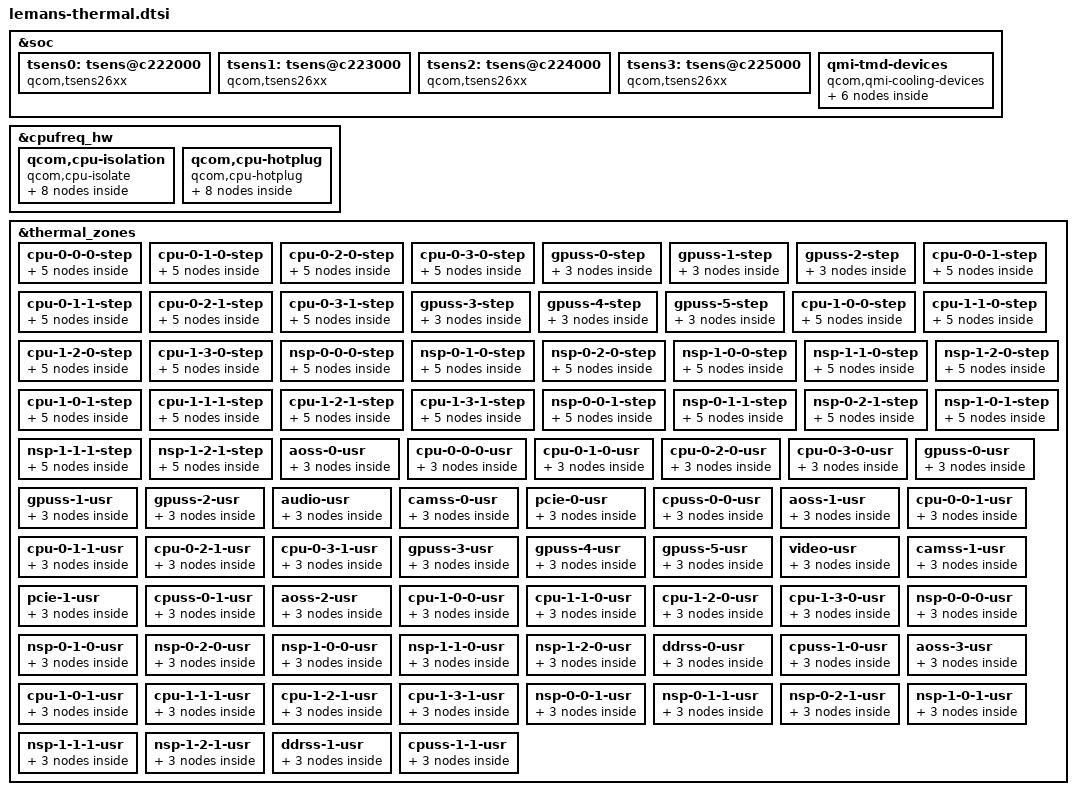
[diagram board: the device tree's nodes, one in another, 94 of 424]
#include <dt-bindings/thermal/thermal_qti.h>

&soc {
	tsens0:tsens@c222000 {
		compatible = "qcom,tsens26xx";
		reg = <0x0C222000 0x8>,
		      <0x0C263000 0x1ff>;
		reg-names = "tsens_srot_physical",
			"tsens_tm_physical";
		interrupts = <GIC_SPI 506 IRQ_TYPE_LEVEL_HIGH>,
			<GIC_SPI 508 IRQ_TYPE_LEVEL_HIGH>;
		interrupt-names = "tsens-upper-lower", "tsens-critical";
		#thermal-sensor-cells = <1>;
	};

	tsens1:tsens@c223000 {
		compatible = "qcom,tsens26xx";
		reg = <0x0C223000 0x8>,
			<0x0C265000 0x1ff>;
		reg-names = "tsens_srot_physical",
			"tsens_tm_physical";
		interrupts = <GIC_SPI 507 IRQ_TYPE_LEVEL_HIGH>,
			<GIC_SPI 509 IRQ_TYPE_LEVEL_HIGH>;
		interrupt-names = "tsens-upper-lower", "tsens-critical";
		#thermal-sensor-cells = <1>;
	};

	tsens2:tsens@c224000 {
		compatible = "qcom,tsens26xx";
		reg = <0x0C224000 0x8>,
			<0x0C251000 0x1ff>;
		reg-names = "tsens_srot_physical",
			"tsens_tm_physical";
		interrupts = <GIC_SPI 572 IRQ_TYPE_LEVEL_HIGH>,
			<GIC_SPI 609 IRQ_TYPE_LEVEL_HIGH>;
		interrupt-names = "tsens-upper-lower", "tsens-critical";
		#thermal-sensor-cells = <1>;
	};

	tsens3:tsens@c225000 {
		compatible = "qcom,tsens26xx";
		reg = <0x0C225000 0x8>,
			<0x0C252000 0x1ff>;
		reg-names = "tsens_srot_physical",
			"tsens_tm_physical";
		interrupts = <GIC_SPI 573 IRQ_TYPE_LEVEL_HIGH>,
			<GIC_SPI 610 IRQ_TYPE_LEVEL_HIGH>;
		interrupt-names = "tsens-upper-lower", "tsens-critical";
		#thermal-sensor-cells = <1>;
	};

	qmi-tmd-devices {
		compatible = "qcom,qmi-cooling-devices";

		cdsp0 {
			qcom,instance-id = <QMI_CDSP_INST_ID>;

			cdsp_sw0: cdsp_sw0 {
				qcom,qmi-dev-name = "cdsp_sw";
				#cooling-cells = <2>;
			};

			cdsp_hw0: cdsp_hw0 {
				qcom,qmi-dev-name = "cdsp_hw";
				#cooling-cells = <2>;
			};
		};

		cdsp1 {
			qcom,instance-id = <QMI_CDSP1_INST_ID>;

			cdsp_sw1: cdsp_sw1 {
				qcom,qmi-dev-name = "cdsp_sw";
				#cooling-cells = <2>;
			};

			cdsp_hw1: cdsp_hw1 {
				qcom,qmi-dev-name = "cdsp_hw";
				#cooling-cells = <2>;
			};
		};
	};
};

&cpufreq_hw {
	qcom,cpu-isolation {
		compatible = "qcom,cpu-isolate";
		cpu0_isolate: cpu0-isolate {
			qcom,cpu = <&CPU0>;
			#cooling-cells = <2>;
		};

		cpu1_isolate: cpu1-isolate {
			qcom,cpu = <&CPU1>;
			#cooling-cells = <2>;
		};

		cpu2_isolate: cpu2-isolate {
			qcom,cpu = <&CPU2>;
			#cooling-cells = <2>;
		};

		cpu3_isolate: cpu3-isolate {
			qcom,cpu = <&CPU3>;
			#cooling-cells = <2>;
		};

		cpu4_isolate: cpu4-isolate {
			qcom,cpu = <&CPU4>;
			#cooling-cells = <2>;
		};

		cpu5_isolate: cpu5-isolate {
			qcom,cpu = <&CPU5>;
			#cooling-cells = <2>;
		};

		cpu6_isolate: cpu6-isolate {
			qcom,cpu = <&CPU6>;
			#cooling-cells = <2>;
		};

		cpu7_isolate: cpu7-isolate {
			qcom,cpu = <&CPU7>;
			#cooling-cells = <2>;
		};
	};

	qcom,cpu-hotplug {
		compatible = "qcom,cpu-hotplug";
		cpu0_hotplug: cpu0-hotplug {
			qcom,cpu = <&CPU0>;
			#cooling-cells = <2>;
		};

		cpu1_hotplug: cpu1-hotplug {
			qcom,cpu = <&CPU1>;
			#cooling-cells = <2>;
		};

		cpu2_hotplug: cpu2-hotplug {
			qcom,cpu = <&CPU2>;
			#cooling-cells = <2>;
		};

		cpu3_hotplug: cpu3-hotplug {
			qcom,cpu = <&CPU3>;
			#cooling-cells = <2>;
		};

		cpu4_hotplug: cpu4-hotplug {
			qcom,cpu = <&CPU4>;
			#cooling-cells = <2>;
		};

		cpu5_hotplug: cpu5-hotplug {
			qcom,cpu = <&CPU5>;
			#cooling-cells = <2>;
		};

		cpu6_hotplug: cpu6-hotplug {
			qcom,cpu = <&CPU6>;
			#cooling-cells = <2>;
		};

		cpu7_hotplug: cpu7-hotplug {
			qcom,cpu = <&CPU7>;
			#cooling-cells = <2>;
		};
	};
};

&thermal_zones {
	cpu-0-0-0-step {
		polling-delay-passive = <0>;
		polling-delay = <0>;
		thermal-governor = "step_wise";
		thermal-sensors = <&tsens0 1>;
		trips {
			cpu000_config: cpu000-config {
				temperature = <116000>;
				hysteresis = <3000>;
				type = "passive";
			};

			cpu000_config1: cpu000-config1 {
				temperature = <115000>;
				hysteresis = <5000>;
				type = "passive";
			};
		};

		cooling-maps {
			cpu000_cdev {
				trip = <&cpu000_config>;
				cooling-device = <&cpu0_isolate 1 1>;
			};
		};
	};

	cpu-0-1-0-step {
		polling-delay-passive = <0>;
		polling-delay = <0>;
		thermal-governor = "step_wise";
		thermal-sensors = <&tsens0 2>;
		trips {
			cpu010_config: cpu010-config {
				temperature = <116000>;
				hysteresis = <3000>;
				type = "passive";
			};

			cpu010_config1: cpu010-config1 {
				temperature = <115000>;
				hysteresis = <5000>;
				type = "passive";
			};
		};

		cooling-maps {
			cpu010_cdev {
				trip = <&cpu010_config>;
				cooling-device = <&cpu1_isolate 1 1>;
			};
		};
	};

	cpu-0-2-0-step {
		polling-delay-passive = <0>;
		polling-delay = <0>;
		thermal-governor = "step_wise";
		thermal-sensors = <&tsens0 3>;
		trips {
			cpu020_config: cpu020-config {
				temperature = <116000>;
				hysteresis = <3000>;
				type = "passive";
			};

			cpu020_config1: cpu020-config1 {
				temperature = <115000>;
				hysteresis = <5000>;
				type = "passive";
			};
		};

		cooling-maps {
			cpu020_cdev {
				trip = <&cpu020_config>;
				cooling-device = <&cpu2_isolate 1 1>;
			};
		};
	};

	cpu-0-3-0-step {
		polling-delay-passive = <0>;
		polling-delay = <0>;
		thermal-governor = "step_wise";
		thermal-sensors = <&tsens0 4>;
		trips {
			cpu030_config: cpu030-config {
				temperature = <116000>;
				hysteresis = <3000>;
				type = "passive";
			};

			cpu030_config1: cpu030-config1 {
				temperature = <115000>;
				hysteresis = <5000>;
				type = "passive";
			};
		};

		cooling-maps {
			cpu030_cdev {
				trip = <&cpu030_config>;
				cooling-device = <&cpu3_isolate 1 1>;
			};
		};
	};

	gpuss-0-step {
		polling-delay-passive = <0>;
		polling-delay = <0>;
		thermal-governor = "step_wise";
		thermal-sensors = <&tsens0 5>;
		trips {
			gpuss0_config: gpuss0-config {
				temperature = <110000>;
				hysteresis = <10000>;
				type = "passive";
			};

			gpuss0_config1: gpuss0-config1 {
				temperature = <115000>;
				hysteresis = <5000>;
				type = "passive";
			};
		};
	};

	gpuss-1-step {
		polling-delay-passive = <0>;
		polling-delay = <0>;
		thermal-governor = "step_wise";
		thermal-sensors = <&tsens0 6>;
		trips {
			gpuss1_config: gpuss1-config {
				temperature = <110000>;
				hysteresis = <10000>;
				type = "passive";
			};

			gpuss1_config1: gpuss1-config1 {
				temperature = <115000>;
				hysteresis = <5000>;
				type = "passive";
			};
		};
	};

	gpuss-2-step {
		polling-delay-passive = <0>;
		polling-delay = <0>;
		thermal-governor = "step_wise";
		thermal-sensors = <&tsens0 7>;
		trips {
			gpuss2_config: gpuss2-config {
				temperature = <110000>;
				hysteresis = <10000>;
				type = "passive";
			};

			gpuss2_config1: gpuss2-config1 {
				temperature = <115000>;
				hysteresis = <5000>;
				type = "passive";
			};
		};
	};

	cpu-0-0-1-step {
		polling-delay-passive = <0>;
		polling-delay = <0>;
		thermal-governor = "step_wise";
		thermal-sensors = <&tsens1 1>;
		trips {
			cpu001_config: cpu001-config {
				temperature = <116000>;
				hysteresis = <3000>;
				type = "passive";
			};

			cpu001_config1: cpu001-config1 {
				temperature = <115000>;
				hysteresis = <5000>;
				type = "passive";
			};
		};

		cooling-maps {
			cpu001_cdev {
				trip = <&cpu001_config>;
				cooling-device = <&cpu0_isolate 1 1>;
			};
		};
	};

	cpu-0-1-1-step {
		polling-delay-passive = <0>;
		polling-delay = <0>;
		thermal-governor = "step_wise";
		thermal-sensors = <&tsens1 2>;
		trips {
			cpu011_config: cpu011-config {
				temperature = <116000>;
				hysteresis = <3000>;
				type = "passive";
			};

			cpu011_config1: cpu011-config1 {
				temperature = <115000>;
				hysteresis = <5000>;
				type = "passive";
			};
		};

		cooling-maps {
			cpu011_cdev {
				trip = <&cpu011_config>;
				cooling-device = <&cpu1_isolate 1 1>;
			};
		};
	};

	cpu-0-2-1-step {
		polling-delay-passive = <0>;
		polling-delay = <0>;
		thermal-governor = "step_wise";
		thermal-sensors = <&tsens1 3>;
		trips {
			cpu021_config: cpu021-config {
				temperature = <116000>;
				hysteresis = <3000>;
				type = "passive";
			};

			cpu021_config1: cpu021-config1 {
				temperature = <115000>;
				hysteresis = <5000>;
				type = "passive";
			};
		};

		cooling-maps {
			cpu021_cdev {
				trip = <&cpu021_config>;
				cooling-device = <&cpu2_isolate 1 1>;
			};
		};
	};

	cpu-0-3-1-step {
		polling-delay-passive = <0>;
		polling-delay = <0>;
		thermal-governor = "step_wise";
		thermal-sensors = <&tsens1 4>;
		trips {
			cpu031_config: cpu031-config {
				temperature = <116000>;
				hysteresis = <3000>;
				type = "passive";
			};

			cpu031_config1: cpu031-config1 {
				temperature = <115000>;
				hysteresis = <5000>;
				type = "passive";
			};
		};

		cooling-maps {
			cpu031_cdev {
				trip = <&cpu031_config>;
				cooling-device = <&cpu3_isolate 1 1>;
			};
		};
	};

	gpuss-3-step {
		polling-delay-passive = <0>;
		polling-delay = <0>;
		thermal-governor = "step_wise";
		thermal-sensors = <&tsens1 5>;
		trips {
			gpuss3_config: gpuss3-config {
				temperature = <110000>;
				hysteresis = <10000>;
				type = "passive";
			};

			gpuss3_config1: gpuss3-config1 {
				temperature = <115000>;
				hysteresis = <5000>;
				type = "passive";
			};
		};
	};

	gpuss-4-step {
		polling-delay-passive = <0>;
		polling-delay = <0>;
		thermal-governor = "step_wise";
		thermal-sensors = <&tsens1 6>;
		trips {
			gpuss4_config: gpuss4-config {
				temperature = <110000>;
				hysteresis = <10000>;
				type = "passive";
			};

			gpuss4_config1: gpuss4-config1 {
				temperature = <115000>;
				hysteresis = <5000>;
				type = "passive";
			};
		};
	};

	gpuss-5-step {
		polling-delay-passive = <0>;
		polling-delay = <0>;
		thermal-governor = "step_wise";
		thermal-sensors = <&tsens1 7>;
		trips {
			gpuss5_config: gpuss5-config {
				temperature = <110000>;
				hysteresis = <10000>;
				type = "passive";
			};

			gpuss5_config1: gpuss5-config1 {
				temperature = <115000>;
				hysteresis = <5000>;
				type = "passive";
			};
		};
	};

	cpu-1-0-0-step {
		polling-delay-passive = <0>;
		polling-delay = <0>;
		thermal-governor = "step_wise";
		thermal-sensors = <&tsens2 1>;
		trips {
			cpu100_config: cpu100-config {
				temperature = <116000>;
				hysteresis = <3000>;
				type = "passive";
			};

			cpu100_config1: cpu100-config1 {
				temperature = <115000>;
				hysteresis = <5000>;
				type = "passive";
			};
		};

		cooling-maps {
			cpu100_cdev {
				trip = <&cpu100_config>;
				cooling-device = <&cpu4_isolate 1 1>;
			};
		};
	};

	cpu-1-1-0-step {
		polling-delay-passive = <0>;
		polling-delay = <0>;
		thermal-governor = "step_wise";
		thermal-sensors = <&tsens2 2>;
		trips {
			cpu110_config: cpu110-config {
				temperature = <116000>;
				hysteresis = <3000>;
				type = "passive";
			};

			cpu110_config1: cpu110-config1 {
				temperature = <115000>;
				hysteresis = <5000>;
				type = "passive";
			};
		};

		cooling-maps {
			cpu110_cdev {
				trip = <&cpu110_config>;
				cooling-device = <&cpu5_isolate 1 1>;
			};
		};
	};

	cpu-1-2-0-step {
		polling-delay-passive = <0>;
		polling-delay = <0>;
		thermal-governor = "step_wise";
		thermal-sensors = <&tsens2 3>;
		trips {
			cpu120_config: cpu120-config {
				temperature = <116000>;
				hysteresis = <3000>;
				type = "passive";
			};

			cpu120_config1: cpu120-config1 {
				temperature = <115000>;
				hysteresis = <5000>;
				type = "passive";
			};
		};

		cooling-maps {
			cpu120_cdev {
				trip = <&cpu120_config>;
				cooling-device = <&cpu6_isolate 1 1>;
			};
		};
	};

	cpu-1-3-0-step {
		polling-delay-passive = <0>;
		polling-delay = <0>;
		thermal-governor = "step_wise";
		thermal-sensors = <&tsens2 4>;
		trips {
			cpu130_config: cpu130-config {
				temperature = <116000>;
				hysteresis = <3000>;
				type = "passive";
			};

			cpu130_config1: cpu130-config1 {
				temperature = <115000>;
				hysteresis = <5000>;
				type = "passive";
			};
		};

		cooling-maps {
			cpu130_cdev {
				trip = <&cpu130_config>;
				cooling-device = <&cpu7_isolate 1 1>;
			};
		};
	};

	nsp-0-0-0-step {
		polling-delay-passive = <0>;
		polling-delay = <0>;
		thermal-governor = "step_wise";
		thermal-sensors = <&tsens2 5>;
		trips {
			nsp000_config: nsp000-config {
				temperature = <105000>;
				hysteresis = <10000>;
				type = "passive";
			};

			nsp000_config1: nsp000-config1 {
				temperature = <115000>;
				hysteresis = <5000>;
				type = "passive";
			};
		};

		cooling-maps {
			nsp000_cdev {
				trip = <&nsp000_config>;
				cooling-device = <&cdsp_sw0 THERMAL_NO_LIMIT
								THERMAL_NO_LIMIT>;
			};
		};
	};

	nsp-0-1-0-step {
		polling-delay-passive = <0>;
		polling-delay = <0>;
		thermal-governor = "step_wise";
		thermal-sensors = <&tsens2 6>;
		trips {
			nsp010_config: nsp010-config {
				temperature = <105000>;
				hysteresis = <10000>;
				type = "passive";
			};

			nsp010_config1: nsp010-config1 {
				temperature = <115000>;
				hysteresis = <5000>;
				type = "passive";
			};
		};

		cooling-maps {
			nsp010_cdev {
				trip = <&nsp010_config>;
				cooling-device = <&cdsp_sw0 THERMAL_NO_LIMIT
								THERMAL_NO_LIMIT>;
			};
		};
	};

	nsp-0-2-0-step {
		polling-delay-passive = <0>;
		polling-delay = <0>;
		thermal-governor = "step_wise";
		thermal-sensors = <&tsens2 7>;
		trips {
			nsp020_config: nsp020-config {
				temperature = <105000>;
				hysteresis = <10000>;
				type = "passive";
			};

			nsp020_config1: nsp020-config1 {
				temperature = <115000>;
				hysteresis = <5000>;
				type = "passive";
			};
		};

		cooling-maps {
			nsp020_cdev {
				trip = <&nsp020_config>;
				cooling-device = <&cdsp_sw0 THERMAL_NO_LIMIT
								THERMAL_NO_LIMIT>;
			};
		};
	};

	nsp-1-0-0-step {
		polling-delay-passive = <0>;
		polling-delay = <0>;
		thermal-governor = "step_wise";
		thermal-sensors = <&tsens2 8>;
		trips {
			nsp100_config: nsp100-config {
				temperature = <105000>;
				hysteresis = <10000>;
				type = "passive";
			};

			nsp100_config1: nsp100-config1 {
				temperature = <115000>;
				hysteresis = <5000>;
				type = "passive";
			};
		};

		cooling-maps {
			nsp100_cdev {
				trip = <&nsp100_config>;
				cooling-device = <&cdsp_sw1 THERMAL_NO_LIMIT
								THERMAL_NO_LIMIT>;
			};
		};
	};

	nsp-1-1-0-step {
		polling-delay-passive = <0>;
		polling-delay = <0>;
		thermal-governor = "step_wise";
		thermal-sensors = <&tsens2 9>;
		trips {
			nsp110_config: nsp110-config {
				temperature = <105000>;
				hysteresis = <10000>;
				type = "passive";
			};

			nsp110_config1: nsp110-config1 {
				temperature = <115000>;
				hysteresis = <5000>;
				type = "passive";
			};
		};

		cooling-maps {
			nsp110_cdev {
				trip = <&nsp110_config>;
				cooling-device = <&cdsp_sw1 THERMAL_NO_LIMIT
								THERMAL_NO_LIMIT>;
			};
		};
	};

	nsp-1-2-0-step {
		polling-delay-passive = <0>;
		polling-delay = <0>;
		thermal-governor = "step_wise";
		thermal-sensors = <&tsens2 10>;
		trips {
			nsp120_config: nsp120-config {
				temperature = <105000>;
				hysteresis = <10000>;
				type = "passive";
			};

			nsp120_config1: nsp120-config1 {
				temperature = <115000>;
				hysteresis = <5000>;
				type = "passive";
			};
		};

		cooling-maps {
			nsp120_cdev {
				trip = <&nsp120_config>;
				cooling-device = <&cdsp_sw1 THERMAL_NO_LIMIT
								THERMAL_NO_LIMIT>;
			};
		};
	};

	cpu-1-0-1-step {
		polling-delay-passive = <0>;
		polling-delay = <0>;
		thermal-governor = "step_wise";
		thermal-sensors = <&tsens3 1>;
		trips {
			cpu101_config: cpu101-config {
				temperature = <116000>;
				hysteresis = <3000>;
				type = "passive";
			};

			cpu101_config1: cpu101-config1 {
				temperature = <115000>;
				hysteresis = <5000>;
				type = "passive";
			};
		};

		cooling-maps {
			cpu101_cdev {
				trip = <&cpu101_config>;
				cooling-device = <&cpu4_isolate 1 1>;
			};
		};
	};

	cpu-1-1-1-step {
		polling-delay-passive = <0>;
		polling-delay = <0>;
		thermal-governor = "step_wise";
		thermal-sensors = <&tsens3 2>;
		trips {
			cpu111_config: cpu111-config {
				temperature = <116000>;
				hysteresis = <3000>;
				type = "passive";
			};

			cpu111_config1: cpu111-config1 {
				temperature = <115000>;
				hysteresis = <5000>;
				type = "passive";
			};
		};

		cooling-maps {
			cpu111_cdev {
				trip = <&cpu111_config>;
				cooling-device = <&cpu5_isolate 1 1>;
			};
		};
	};

	cpu-1-2-1-step {
		polling-delay-passive = <0>;
		polling-delay = <0>;
		thermal-governor = "step_wise";
		thermal-sensors = <&tsens3 3>;
		trips {
			cpu121_config: cpu121-config {
				temperature = <116000>;
				hysteresis = <3000>;
				type = "passive";
			};

			cpu121_config1: cpu121-config1 {
				temperature = <115000>;
				hysteresis = <5000>;
				type = "passive";
			};
		};

		cooling-maps {
			cpu121_cdev {
				trip = <&cpu121_config>;
				cooling-device = <&cpu6_isolate 1 1>;
			};
		};
	};

	cpu-1-3-1-step {
		polling-delay-passive = <0>;
		polling-delay = <0>;
		thermal-governor = "step_wise";
		thermal-sensors = <&tsens3 4>;
		trips {
			cpu131_config: cpu131-config {
				temperature = <116000>;
				hysteresis = <3000>;
				type = "passive";
			};

			cpu131_config1: cpu131-config1 {
				temperature = <115000>;
				hysteresis = <5000>;
				type = "passive";
			};
		};

		cooling-maps {
			cpu131_cdev {
				trip = <&cpu131_config>;
				cooling-device = <&cpu7_isolate 1 1>;
			};
		};
	};

	nsp-0-0-1-step {
		polling-delay-passive = <0>;
		polling-delay = <0>;
		thermal-governor = "step_wise";
		thermal-sensors = <&tsens3 5>;
		trips {
			nsp001_config: nsp001-config {
				temperature = <105000>;
				hysteresis = <10000>;
				type = "passive";
			};

			nsp001_config1: nsp001-config1 {
				temperature = <115000>;
				hysteresis = <5000>;
				type = "passive";
			};
		};

		cooling-maps {
			nsp001_cdev {
				trip = <&nsp001_config>;
				cooling-device = <&cdsp_sw0 THERMAL_NO_LIMIT
								THERMAL_NO_LIMIT>;
			};
		};
	};

	nsp-0-1-1-step {
		polling-delay-passive = <0>;
		polling-delay = <0>;
		thermal-governor = "step_wise";
		thermal-sensors = <&tsens3 6>;
		trips {
			nsp011_config: nsp011-config {
				temperature = <105000>;
				hysteresis = <10000>;
				type = "passive";
			};

			nsp011_config1: nsp011-config1 {
				temperature = <115000>;
				hysteresis = <5000>;
				type = "passive";
			};
		};

		cooling-maps {
			nsp011_cdev {
				trip = <&nsp011_config>;
				cooling-device = <&cdsp_sw0 THERMAL_NO_LIMIT
								THERMAL_NO_LIMIT>;
			};
		};
	};

	nsp-0-2-1-step {
		polling-delay-passive = <0>;
		polling-delay = <0>;
		thermal-governor = "step_wise";
		thermal-sensors = <&tsens3 7>;
		trips {
			nsp021_config: nsp021-config {
				temperature = <105000>;
				hysteresis = <10000>;
				type = "passive";
			};

			nsp021_config1: nsp021-config1 {
				temperature = <115000>;
				hysteresis = <5000>;
				type = "passive";
			};
		};

		cooling-maps {
			nsp021_cdev {
				trip = <&nsp021_config>;
				cooling-device = <&cdsp_sw0 THERMAL_NO_LIMIT
								THERMAL_NO_LIMIT>;
			};
		};
	};

	nsp-1-0-1-step {
		polling-delay-passive = <0>;
		polling-delay = <0>;
		thermal-governor = "step_wise";
		thermal-sensors = <&tsens3 8>;
		trips {
			nsp101_config: nsp101-config {
				temperature = <105000>;
				hysteresis = <10000>;
				type = "passive";
			};

			nsp101_config1: nsp101-config1 {
				temperature = <115000>;
				hysteresis = <5000>;
				type = "passive";
			};
		};

		cooling-maps {
			nsp101_cdev {
				trip = <&nsp101_config>;
				cooling-device = <&cdsp_sw1 THERMAL_NO_LIMIT
								THERMAL_NO_LIMIT>;
			};
		};
	};

	nsp-1-1-1-step {
		polling-delay-passive = <0>;
		polling-delay = <0>;
		thermal-governor = "step_wise";
		thermal-sensors = <&tsens3 9>;
		trips {
			nsp111_config: nsp111-config {
				temperature = <105000>;
				hysteresis = <10000>;
				type = "passive";
			};

			nsp111_config1: nsp111-config1 {
				temperature = <115000>;
				hysteresis = <5000>;
				type = "passive";
			};
		};

		cooling-maps {
			nsp111_cdev {
				trip = <&nsp111_config>;
				cooling-device = <&cdsp_sw1 THERMAL_NO_LIMIT
								THERMAL_NO_LIMIT>;
			};
		};
	};

	nsp-1-2-1-step {
		polling-delay-passive = <0>;
		polling-delay = <0>;
		thermal-governor = "step_wise";
		thermal-sensors = <&tsens3 10>;
		trips {
			nsp121_config: nsp121-config {
				temperature = <105000>;
				hysteresis = <10000>;
				type = "passive";
			};

			nsp121_config1: nsp121-config1 {
				temperature = <115000>;
				hysteresis = <5000>;
				type = "passive";
			};
		};

		cooling-maps {
			nsp121_cdev {
				trip = <&nsp121_config>;
				cooling-device = <&cdsp_sw1 THERMAL_NO_LIMIT
								THERMAL_NO_LIMIT>;
			};
		};
	};

	aoss-0-usr {
		polling-delay-passive = <0>;
		polling-delay = <0>;
		thermal-governor = "user_space";
		thermal-sensors = <&tsens0 0>;
		trips {
			active-config0 {
				temperature = <125000>;
				hysteresis = <1000>;
				type = "passive";
			};

			reset-mon-cfg {
				temperature = <115000>;
				hysteresis = <5000>;
				type = "passive";
			};
		};
	};

	cpu-0-0-0-usr {
		polling-delay-passive = <0>;
		polling-delay = <0>;
		thermal-governor = "user_space";
		thermal-sensors = <&tsens0 1>;
		trips {
			active-config0 {
				temperature = <125000>;
				hysteresis = <1000>;
				type = "passive";
			};

			reset-mon-cfg {
				temperature = <115000>;
				hysteresis = <5000>;
				type = "passive";
			};
		};
	};

	cpu-0-1-0-usr {
		polling-delay-passive = <0>;
		polling-delay = <0>;
		thermal-governor = "user_space";
		thermal-sensors = <&tsens0 2>;
		trips {
			active-config0 {
				temperature = <125000>;
				hysteresis = <1000>;
				type = "passive";
			};

			reset-mon-cfg {
				temperature = <115000>;
				hysteresis = <5000>;
				type = "passive";
			};
		};
	};

	cpu-0-2-0-usr {
		polling-delay-passive = <0>;
		polling-delay = <0>;
		thermal-governor = "user_space";
		thermal-sensors = <&tsens0 3>;
		trips {
			active-config0 {
				temperature = <125000>;
				hysteresis = <1000>;
				type = "passive";
			};

			reset-mon-cfg {
				temperature = <115000>;
				hysteresis = <5000>;
				type = "passive";
			};
		};
	};

	cpu-0-3-0-usr {
		polling-delay-passive = <0>;
		polling-delay = <0>;
		thermal-governor = "user_space";
		thermal-sensors = <&tsens0 4>;
		trips {
			active-config0 {
				temperature = <125000>;
				hysteresis = <1000>;
				type = "passive";
			};

			reset-mon-cfg {
				temperature = <115000>;
				hysteresis = <5000>;
				type = "passive";
			};
		};
	};

	gpuss-0-usr {
		polling-delay-passive = <0>;
		polling-delay = <0>;
		thermal-governor = "user_space";
		thermal-sensors = <&tsens0 5>;
		trips {
			active-config0 {
				temperature = <125000>;
				hysteresis = <1000>;
				type = "passive";
			};

			reset-mon-cfg {
				temperature = <115000>;
				hysteresis = <5000>;
				type = "passive";
			};
		};
	};

	gpuss-1-usr {
		polling-delay-passive = <0>;
		polling-delay = <0>;
		thermal-governor = "user_space";
		thermal-sensors = <&tsens0 6>;
		trips {
			active-config0 {
				temperature = <125000>;
				hysteresis = <1000>;
				type = "passive";
			};

			reset-mon-cfg {
				temperature = <115000>;
				hysteresis = <5000>;
				type = "passive";
			};
		};
	};

	gpuss-2-usr {
		polling-delay-passive = <0>;
		polling-delay = <0>;
		thermal-governor = "user_space";
		thermal-sensors = <&tsens0 7>;
		trips {
			active-config0 {
				temperature = <125000>;
				hysteresis = <1000>;
				type = "passive";
			};

			reset-mon-cfg {
				temperature = <115000>;
				hysteresis = <5000>;
				type = "passive";
			};
		};
	};

	audio-usr {
		polling-delay-passive = <0>;
		polling-delay = <0>;
		thermal-governor = "user_space";
		thermal-sensors = <&tsens0 8>;
		trips {
			active-config0 {
				temperature = <125000>;
				hysteresis = <1000>;
				type = "passive";
			};

			reset-mon-cfg {
				temperature = <115000>;
				hysteresis = <5000>;
				type = "passive";
			};
		};
	};

	camss-0-usr {
		polling-delay-passive = <0>;
		polling-delay = <0>;
		thermal-governor = "user_space";
		thermal-sensors = <&tsens0 9>;
		trips {
			active-config0 {
				temperature = <125000>;
				hysteresis = <1000>;
				type = "passive";
			};

			reset-mon-cfg {
				temperature = <115000>;
				hysteresis = <5000>;
				type = "passive";
			};
		};
	};

	pcie-0-usr {
		polling-delay-passive = <0>;
		polling-delay = <0>;
		thermal-governor = "user_space";
		thermal-sensors = <&tsens0 10>;
		trips {
			active-config0 {
				temperature = <125000>;
				hysteresis = <1000>;
				type = "passive";
			};

			reset-mon-cfg {
				temperature = <115000>;
				hysteresis = <5000>;
				type = "passive";
			};
		};
	};

	cpuss-0-0-usr {
		polling-delay-passive = <0>;
		polling-delay = <0>;
		thermal-governor = "user_space";
		thermal-sensors = <&tsens0 11>;
		trips {
			active-config0 {
				temperature = <125000>;
				hysteresis = <1000>;
				type = "passive";
			};

			reset-mon-cfg {
				temperature = <115000>;
				hysteresis = <5000>;
				type = "passive";
			};
		};
	};

	aoss-1-usr {
		polling-delay-passive = <0>;
		polling-delay = <0>;
		thermal-governor = "user_space";
		thermal-sensors = <&tsens1 0>;
		trips {
			active-config0 {
				temperature = <125000>;
				hysteresis = <1000>;
				type = "passive";
			};

			reset-mon-cfg {
				temperature = <115000>;
				hysteresis = <5000>;
				type = "passive";
			};
		};
	};

	cpu-0-0-1-usr {
		polling-delay-passive = <0>;
		polling-delay = <0>;
		thermal-governor = "user_space";
		thermal-sensors = <&tsens1 1>;
		trips {
			active-config0 {
				temperature = <125000>;
				hysteresis = <1000>;
				type = "passive";
			};

			reset-mon-cfg {
				temperature = <115000>;
				hysteresis = <5000>;
				type = "passive";
			};
		};
	};

	cpu-0-1-1-usr {
		polling-delay-passive = <0>;
		polling-delay = <0>;
		thermal-governor = "user_space";
		thermal-sensors = <&tsens1 2>;
		trips {
			active-config0 {
				temperature = <125000>;
				hysteresis = <1000>;
				type = "passive";
			};

			reset-mon-cfg {
				temperature = <115000>;
				hysteresis = <5000>;
				type = "passive";
			};
		};
	};

	cpu-0-2-1-usr {
		polling-delay-passive = <0>;
		polling-delay = <0>;
		thermal-governor = "user_space";
		thermal-sensors = <&tsens1 3>;
		trips {
			active-config0 {
				temperature = <125000>;
				hysteresis = <1000>;
				type = "passive";
			};

			reset-mon-cfg {
				temperature = <115000>;
				hysteresis = <5000>;
				type = "passive";
			};
		};
	};

	cpu-0-3-1-usr {
		polling-delay-passive = <0>;
		polling-delay = <0>;
		thermal-governor = "user_space";
		thermal-sensors = <&tsens1 4>;
		trips {
			active-config0 {
				temperature = <125000>;
				hysteresis = <1000>;
				type = "passive";
			};

			reset-mon-cfg {
				temperature = <115000>;
				hysteresis = <5000>;
				type = "passive";
			};
		};
	};

	gpuss-3-usr {
		polling-delay-passive = <0>;
		polling-delay = <0>;
		thermal-governor = "user_space";
		thermal-sensors = <&tsens1 5>;
		trips {
			active-config0 {
				temperature = <125000>;
				hysteresis = <1000>;
				type = "passive";
			};

			reset-mon-cfg {
				temperature = <115000>;
				hysteresis = <5000>;
				type = "passive";
			};
		};
	};

	gpuss-4-usr {
		polling-delay-passive = <0>;
		polling-delay = <0>;
		thermal-governor = "user_space";
		thermal-sensors = <&tsens1 6>;
		trips {
			active-config0 {
				temperature = <125000>;
				hysteresis = <1000>;
				type = "passive";
			};

			reset-mon-cfg {
				temperature = <115000>;
				hysteresis = <5000>;
				type = "passive";
			};
		};
	};

	gpuss-5-usr {
		polling-delay-passive = <0>;
		polling-delay = <0>;
		thermal-governor = "user_space";
		thermal-sensors = <&tsens1 7>;
		trips {
			active-config0 {
				temperature = <125000>;
				hysteresis = <1000>;
				type = "passive";
			};

			reset-mon-cfg {
				temperature = <115000>;
				hysteresis = <5000>;
				type = "passive";
			};
		};
	};

	video-usr {
		polling-delay-passive = <0>;
		polling-delay = <0>;
		thermal-governor = "user_space";
		thermal-sensors = <&tsens1 8>;
		trips {
			active-config0 {
				temperature = <125000>;
				hysteresis = <1000>;
				type = "passive";
			};

			reset-mon-cfg {
				temperature = <115000>;
				hysteresis = <5000>;
				type = "passive";
			};
		};
	};

	camss-1-usr {
		polling-delay-passive = <0>;
		polling-delay = <0>;
		thermal-governor = "user_space";
		thermal-sensors = <&tsens1 9>;
		trips {
			active-config0 {
				temperature = <125000>;
				hysteresis = <1000>;
				type = "passive";
			};

			reset-mon-cfg {
				temperature = <115000>;
				hysteresis = <5000>;
				type = "passive";
			};
		};
	};

	pcie-1-usr {
		polling-delay-passive = <0>;
		polling-delay = <0>;
		thermal-governor = "user_space";
		thermal-sensors = <&tsens1 10>;
		trips {
			active-config0 {
				temperature = <125000>;
				hysteresis = <1000>;
				type = "passive";
			};

			reset-mon-cfg {
				temperature = <115000>;
				hysteresis = <5000>;
				type = "passive";
			};
		};
	};

	cpuss-0-1-usr {
		polling-delay-passive = <0>;
		polling-delay = <0>;
		thermal-governor = "user_space";
		thermal-sensors = <&tsens1 11>;
		trips {
			active-config0 {
				temperature = <125000>;
				hysteresis = <1000>;
				type = "passive";
			};

			reset-mon-cfg {
				temperature = <115000>;
				hysteresis = <5000>;
				type = "passive";
			};
		};
	};

	aoss-2-usr {
		polling-delay-passive = <0>;
		polling-delay = <0>;
		thermal-governor = "user_space";
		thermal-sensors = <&tsens2 0>;
		trips {
			active-config0 {
				temperature = <125000>;
				hysteresis = <1000>;
				type = "passive";
			};

			reset-mon-cfg {
				temperature = <115000>;
				hysteresis = <5000>;
				type = "passive";
			};
		};
	};

	cpu-1-0-0-usr {
		polling-delay-passive = <0>;
		polling-delay = <0>;
		thermal-governor = "user_space";
		thermal-sensors = <&tsens2 1>;
		trips {
			active-config0 {
				temperature = <125000>;
				hysteresis = <1000>;
				type = "passive";
			};

			reset-mon-cfg {
				temperature = <115000>;
				hysteresis = <5000>;
				type = "passive";
			};
		};
	};

	cpu-1-1-0-usr {
		polling-delay-passive = <0>;
		polling-delay = <0>;
		thermal-governor = "user_space";
		thermal-sensors = <&tsens2 2>;
		trips {
			active-config0 {
				temperature = <125000>;
				hysteresis = <1000>;
				type = "passive";
			};

			reset-mon-cfg {
				temperature = <115000>;
				hysteresis = <5000>;
				type = "passive";
			};
		};
	};

	cpu-1-2-0-usr {
		polling-delay-passive = <0>;
		polling-delay = <0>;
		thermal-governor = "user_space";
		thermal-sensors = <&tsens2 3>;
		trips {
			active-config0 {
				temperature = <125000>;
				hysteresis = <1000>;
				type = "passive";
			};

			reset-mon-cfg {
				temperature = <115000>;
				hysteresis = <5000>;
				type = "passive";
			};
		};
	};

	cpu-1-3-0-usr {
		polling-delay-passive = <0>;
		polling-delay = <0>;
		thermal-governor = "user_space";
		thermal-sensors = <&tsens2 4>;
		trips {
			active-config0 {
				temperature = <125000>;
				hysteresis = <1000>;
				type = "passive";
			};

			reset-mon-cfg {
				temperature = <115000>;
				hysteresis = <5000>;
				type = "passive";
			};
		};
	};

	nsp-0-0-0-usr {
		polling-delay-passive = <0>;
		polling-delay = <0>;
		thermal-governor = "user_space";
		thermal-sensors = <&tsens2 5>;
		trips {
			active-config0 {
				temperature = <125000>;
				hysteresis = <1000>;
				type = "passive";
			};

			reset-mon-cfg {
				temperature = <115000>;
				hysteresis = <5000>;
				type = "passive";
			};
		};
	};

	nsp-0-1-0-usr {
		polling-delay-passive = <0>;
		polling-delay = <0>;
		thermal-governor = "user_space";
		thermal-sensors = <&tsens2 6>;
		trips {
			active-config0 {
				temperature = <125000>;
				hysteresis = <1000>;
				type = "passive";
			};

			reset-mon-cfg {
				temperature = <115000>;
				hysteresis = <5000>;
				type = "passive";
			};
		};
	};

	nsp-0-2-0-usr {
		polling-delay-passive = <0>;
		polling-delay = <0>;
		thermal-governor = "user_space";
		thermal-sensors = <&tsens2 7>;
		trips {
			active-config0 {
				temperature = <125000>;
				hysteresis = <1000>;
				type = "passive";
			};

			reset-mon-cfg {
				temperature = <115000>;
				hysteresis = <5000>;
				type = "passive";
			};
		};
	};

	nsp-1-0-0-usr {
		polling-delay-passive = <0>;
		polling-delay = <0>;
		thermal-governor = "user_space";
		thermal-sensors = <&tsens2 8>;
		trips {
			active-config0 {
				temperature = <125000>;
				hysteresis = <1000>;
				type = "passive";
			};

			reset-mon-cfg {
				temperature = <115000>;
				hysteresis = <5000>;
				type = "passive";
			};
		};
	};

	nsp-1-1-0-usr {
		polling-delay-passive = <0>;
		polling-delay = <0>;
		thermal-governor = "user_space";
		thermal-sensors = <&tsens2 9>;
		trips {
			active-config0 {
				temperature = <125000>;
				hysteresis = <1000>;
				type = "passive";
			};

			reset-mon-cfg {
				temperature = <115000>;
				hysteresis = <5000>;
				type = "passive";
			};
		};
	};

	nsp-1-2-0-usr {
		polling-delay-passive = <0>;
		polling-delay = <0>;
		thermal-governor = "user_space";
		thermal-sensors = <&tsens2 10>;
		trips {
			active-config0 {
				temperature = <125000>;
				hysteresis = <1000>;
				type = "passive";
			};

			reset-mon-cfg {
				temperature = <115000>;
				hysteresis = <5000>;
				type = "passive";
			};
		};
	};

	ddrss-0-usr {
		polling-delay-passive = <0>;
		polling-delay = <0>;
		thermal-governor = "user_space";
		thermal-sensors = <&tsens2 11>;
		trips {
			active-config0 {
				temperature = <125000>;
				hysteresis = <1000>;
				type = "passive";
			};

			reset-mon-cfg {
				temperature = <115000>;
				hysteresis = <5000>;
				type = "passive";
			};
		};
	};

	cpuss-1-0-usr {
		polling-delay-passive = <0>;
		polling-delay = <0>;
		thermal-governor = "user_space";
		thermal-sensors = <&tsens2 12>;
		trips {
			active-config0 {
				temperature = <125000>;
				hysteresis = <1000>;
				type = "passive";
			};

			reset-mon-cfg {
				temperature = <115000>;
				hysteresis = <5000>;
				type = "passive";
			};
		};
	};

	aoss-3-usr {
		polling-delay-passive = <0>;
		polling-delay = <0>;
		thermal-governor = "user_space";
		thermal-sensors = <&tsens3 0>;
		trips {
			active-config0 {
				temperature = <125000>;
				hysteresis = <1000>;
				type = "passive";
			};

			reset-mon-cfg {
				temperature = <115000>;
				hysteresis = <5000>;
				type = "passive";
			};
		};
	};

	cpu-1-0-1-usr {
		polling-delay-passive = <0>;
		polling-delay = <0>;
		thermal-governor = "user_space";
		thermal-sensors = <&tsens3 1>;
		trips {
			active-config0 {
				temperature = <125000>;
				hysteresis = <1000>;
				type = "passive";
			};

			reset-mon-cfg {
				temperature = <115000>;
				hysteresis = <5000>;
				type = "passive";
			};
		};
	};

	cpu-1-1-1-usr {
		polling-delay-passive = <0>;
		polling-delay = <0>;
		thermal-governor = "user_space";
		thermal-sensors = <&tsens3 2>;
		trips {
			active-config0 {
				temperature = <125000>;
				hysteresis = <1000>;
				type = "passive";
			};

			reset-mon-cfg {
				temperature = <115000>;
				hysteresis = <5000>;
				type = "passive";
			};
		};
	};

	cpu-1-2-1-usr {
		polling-delay-passive = <0>;
		polling-delay = <0>;
		thermal-governor = "user_space";
		thermal-sensors = <&tsens3 3>;
		trips {
			active-config0 {
				temperature = <125000>;
				hysteresis = <1000>;
				type = "passive";
			};

			reset-mon-cfg {
				temperature = <115000>;
				hysteresis = <5000>;
				type = "passive";
			};
		};
	};

	cpu-1-3-1-usr {
		polling-delay-passive = <0>;
		polling-delay = <0>;
		thermal-governor = "user_space";
		thermal-sensors = <&tsens3 4>;
		trips {
			active-config0 {
				temperature = <125000>;
				hysteresis = <1000>;
				type = "passive";
			};

			reset-mon-cfg {
				temperature = <115000>;
				hysteresis = <5000>;
				type = "passive";
			};
		};
	};

	nsp-0-0-1-usr {
		polling-delay-passive = <0>;
		polling-delay = <0>;
		thermal-governor = "user_space";
		thermal-sensors = <&tsens3 5>;
		trips {
			active-config0 {
				temperature = <125000>;
				hysteresis = <1000>;
				type = "passive";
			};

			reset-mon-cfg {
				temperature = <115000>;
				hysteresis = <5000>;
				type = "passive";
			};
		};
	};

	nsp-0-1-1-usr {
		polling-delay-passive = <0>;
		polling-delay = <0>;
		thermal-governor = "user_space";
		thermal-sensors = <&tsens3 6>;
		trips {
			active-config0 {
				temperature = <125000>;
				hysteresis = <1000>;
				type = "passive";
			};

			reset-mon-cfg {
				temperature = <115000>;
				hysteresis = <5000>;
				type = "passive";
			};
		};
	};

	nsp-0-2-1-usr {
		polling-delay-passive = <0>;
		polling-delay = <0>;
		thermal-governor = "user_space";
		thermal-sensors = <&tsens3 7>;
		trips {
			active-config0 {
				temperature = <125000>;
				hysteresis = <1000>;
				type = "passive";
			};

			reset-mon-cfg {
				temperature = <115000>;
				hysteresis = <5000>;
				type = "passive";
			};
		};
	};

	nsp-1-0-1-usr {
		polling-delay-passive = <0>;
		polling-delay = <0>;
		thermal-governor = "user_space";
		thermal-sensors = <&tsens3 8>;
		trips {
			active-config0 {
				temperature = <125000>;
				hysteresis = <1000>;
				type = "passive";
			};

			reset-mon-cfg {
				temperature = <115000>;
				hysteresis = <5000>;
				type = "passive";
			};
		};
	};

	nsp-1-1-1-usr {
		polling-delay-passive = <0>;
		polling-delay = <0>;
		thermal-governor = "user_space";
		thermal-sensors = <&tsens3 9>;
		trips {
			active-config0 {
				temperature = <125000>;
				hysteresis = <1000>;
				type = "passive";
			};

			reset-mon-cfg {
				temperature = <115000>;
				hysteresis = <5000>;
				type = "passive";
			};
		};
	};

	nsp-1-2-1-usr {
		polling-delay-passive = <0>;
		polling-delay = <0>;
		thermal-governor = "user_space";
		thermal-sensors = <&tsens3 10>;
		trips {
			active-config0 {
				temperature = <125000>;
				hysteresis = <1000>;
				type = "passive";
			};

			reset-mon-cfg {
				temperature = <115000>;
				hysteresis = <5000>;
				type = "passive";
			};
		};
	};

	ddrss-1-usr {
		polling-delay-passive = <0>;
		polling-delay = <0>;
		thermal-governor = "user_space";
		thermal-sensors = <&tsens3 11>;
		trips {
			active-config0 {
				temperature = <125000>;
				hysteresis = <1000>;
				type = "passive";
			};

			reset-mon-cfg {
				temperature = <115000>;
				hysteresis = <5000>;
				type = "passive";
			};
		};
	};

	cpuss-1-1-usr {
		polling-delay-passive = <0>;
		polling-delay = <0>;
		thermal-governor = "user_space";
		thermal-sensors = <&tsens3 12>;
		trips {
			active-config0 {
				temperature = <125000>;
				hysteresis = <1000>;
				type = "passive";
			};

			reset-mon-cfg {
				temperature = <115000>;
				hysteresis = <5000>;
				type = "passive";
			};
		};
	};
};

